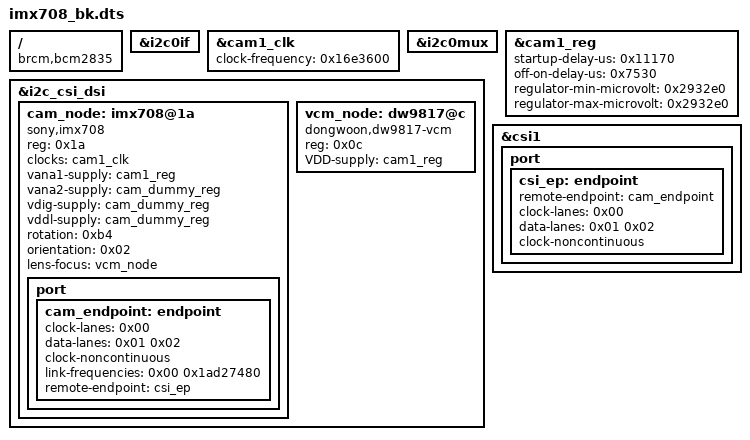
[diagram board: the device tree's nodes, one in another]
/dts-v1/;
/plugin/;

/ {
	compatible = "brcm,bcm2835";

	fragment@0 {
		target = <&i2c0if>;

		__overlay__ {
			status = "okay";
		};
	};

	clk_frag: fragment@1 {
		target = <&cam1_clk>;
		phandle = <0x07>;

		__overlay__ {
			status = "okay";
			clock-frequency = <0x16e3600>;
		};
	};

	fragment@2 {
		target = <&i2c0mux>;

		__overlay__ {
			status = "okay";
		};
	};

	reg_frag: fragment@3 {
		target = <&cam1_reg>;
		phandle = <0x08>;

		cam_reg: __overlay__ {
			startup-delay-us = <0x11170>;
			off-on-delay-us = <0x7530>;
			regulator-min-microvolt = <0x2932e0>;
			regulator-max-microvolt = <0x2932e0>;
			phandle = <0x09>;
		};
	};

	fragment@4 {
		target = <&cam_node>;

		__overlay__ {
			lens-focus = <&vcm_node>;
		};
	};

	i2c_frag: fragment@100 {
		target = <&i2c_csi_dsi>;
		phandle = <0x05>;

		__overlay__ {
			#address-cells = <0x01>;
			#size-cells = <0x00>;
			status = "okay";

			cam_node: imx708@1a {
				compatible = "sony,imx708";
				reg = <0x1a>;
				status = "okay";
				clocks = <&cam1_clk>;
				clock-names = "inclk";
				vana1-supply = <&cam1_reg>;
				vana2-supply = <&cam_dummy_reg>;
				vdig-supply = <&cam_dummy_reg>;
				vddl-supply = <&cam_dummy_reg>;
				rotation = <0xb4>;
				orientation = <0x02>;
				phandle = <0x01>;

				port {

					cam_endpoint: endpoint {
						clock-lanes = <0x00>;
						data-lanes = <0x01 0x02>;
						clock-noncontinuous;
						link-frequencies = <0x00 0x1ad27480>;
						remote-endpoint = <&csi_ep>;
						phandle = <0x04>;
					};
				};
			};

			vcm_node: dw9817@c {
				compatible = "dongwoon,dw9817-vcm";
				reg = <0x0c>;
				status = "okay";
				VDD-supply = <&cam1_reg>;
				phandle = <0x02>;
			};
		};
	};

	csi_frag: fragment@101 {
		target = <&csi1>;
		phandle = <0x06>;

		csi: __overlay__ {
			status = "okay";
			phandle = <0x0a>;

			port {

				csi_ep: endpoint {
					remote-endpoint = <&cam_endpoint>;
					clock-lanes = <0x00>;
					data-lanes = <0x01 0x02>;
					clock-noncontinuous;
					phandle = <0x03>;
				};
			};
		};
	};

	fragment@102 {
		target = <&csi1>;

		__dormant__ {
			compatible = "brcm,bcm2835-unicam-legacy";
		};
	};

	__overrides__ {
		rotation = <&cam_node>, "rotation:0";
		orientation = <&cam_node>, "orientation:0";
		media-controller = [00 00 00 00 21 31 30 32 00];
		cam0 = <&i2c_frag>, "target:0=", <&i2c_csi_dsi0>, <&csi_frag>, "target:0=", <&csi0>, <&clk_frag>, "target:0=", <&cam0_clk>, <&reg_frag>, "target:0=", <&cam0_reg>, <&cam_node>, "clocks:0=", <&cam0_clk>, <&cam_node>, "vana1-supply:0=", <&cam0_reg>, <&vcm_node>, "VDD-supply:0=", <&cam0_reg>;
		vcm = <&vcm_node>, "status", "", "", "", "", "=4";
		link-frequency = <&cam_endpoint>, "link-frequencies#0";
	};

	__symbols__ {
		clk_frag = "/fragment@1";
		reg_frag = "/fragment@3";
		cam_reg = "/fragment@3/__overlay__";
		i2c_frag = "/fragment@100";
		cam_node = "/fragment@100/__overlay__/imx708@1a";
		cam_endpoint = "/fragment@100/__overlay__/imx708@1a/port/endpoint";
		vcm_node = "/fragment@100/__overlay__/dw9817@c";
		csi_frag = "/fragment@101";
		csi = "/fragment@101/__overlay__";
		csi_ep = "/fragment@101/__overlay__/port/endpoint";
	};

	__fixups__ {
		i2c0if = "/fragment@0:target:0";
		cam1_clk = "/fragment@1:target:0", "/fragment@100/__overlay__/imx708@1a:clocks:0";
		i2c0mux = "/fragment@2:target:0";
		cam1_reg = "/fragment@3:target:0", "/fragment@100/__overlay__/imx708@1a:vana1-supply:0", "/fragment@100/__overlay__/dw9817@c:VDD-supply:0";
		i2c_csi_dsi = "/fragment@100:target:0";
		cam_dummy_reg = "/fragment@100/__overlay__/imx708@1a:vana2-supply:0", "/fragment@100/__overlay__/imx708@1a:vdig-supply:0", "/fragment@100/__overlay__/imx708@1a:vddl-supply:0";
		csi1 = "/fragment@101:target:0", "/fragment@102:target:0";
		i2c_csi_dsi0 = "/__overrides__:cam0:14";
		csi0 = "/__overrides__:cam0:32";
		cam0_clk = "/__overrides__:cam0:50", "/__overrides__:cam0:86";
		cam0_reg = "/__overrides__:cam0:68", "/__overrides__:cam0:110", "/__overrides__:cam0:132";
	};

	__local_fixups__ {

		fragment@4 {
			target = <0x00>;

			__overlay__ {
				lens-focus = <0x00>;
			};
		};

		fragment@100 {

			__overlay__ {

				imx708@1a {

					port {

						endpoint {
							remote-endpoint = <0x00>;
						};
					};
				};
			};
		};

		fragment@101 {

			__overlay__ {

				port {

					endpoint {
						remote-endpoint = <0x00>;
					};
				};
			};
		};

		__overrides__ {
			rotation = <0x00>;
			orientation = <0x00>;
			cam0 = <0x00 0x12 0x24 0x36 0x48 0x5a 0x72>;
			vcm = <0x00>;
			link-frequency = <0x00>;
		};
	};
};
